# MWPR1516 register map
Vendor: Freescale Semiconductor, Inc.; Series: Kinetis; File version: 1.6
CPU: CM0PLUS r0p0, little endian, no MPU, no FPU, VTOR, 2 interrupt priority bits
Registers are 8-bit, read-write, reset 0x0 unless marked. A register's access mark holds for its fields unless they carry their own. Offsets are from the block's base; [hi:lo] are bit positions; {n}, {i} and the like mark numbered series.

## PORT — Port control and interrupts
Base 0x40049000; register names take the prefix PORT_
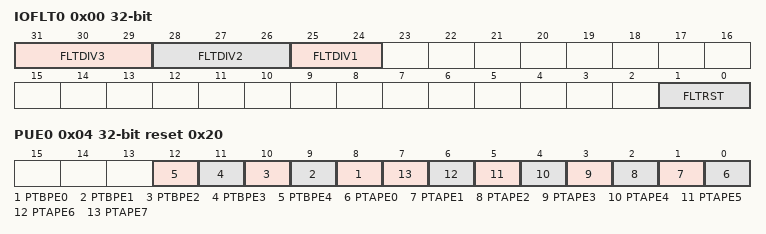
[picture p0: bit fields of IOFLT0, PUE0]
0x00 IOFLT0 32-bit — Port Filter Control Register 0
  [31:29] FLTDIV3 — Filter Division Set 3
    0=LPOCLK; 1=LPOCLK/2; 2=LPOCLK/4; 3=LPOCLK/8; 4=LPOCLK/16; 5=LPOCLK/32; 6=LPOCLK/64; 7=LPOCLK/128
  [28:26] FLTDIV2 — Filter Division Set 2
    0=BUSCLK/32; 1=BUSCLK/64; 2=BUSCLK/128; 3=BUSCLK/256; 4=BUSCLK/512; 5=BUSCLK/1024; 6=BUSCLK/2048; 7=BUSCLK/4096
  [25:24] FLTDIV1 — Filter Division Set 1
    0=BUSCLK/2; 1=BUSCLK/4; 2=BUSCLK/8; 3=BUSCLK/16
  [1:0] FLTRST — Filter Selection for Input from RESET
    0=No filter; 1=Selects FLTDIV1, and will switch to FLTDIV3 in Stop mode automatically; 2=Selects FLTDIV2, and will switch to FLTDIV3 in Stop mode automatically; 3=FLTDIV3
0x04 PUE0 32-bit reset 0x20 — Port Pullup Enable Register 0
  [n+8] PTBPE{n} (n=0..4) — Pull Enable for Port B Bit {n}
    0=Pullup is disabled for port B bit {n}; 1=Pullup is enabled for port B bit {n}
  [n] PTAPE{n} (n=0..7) — Pull Enable for Port A Bit {n}
    0=Pullup is disabled for port A bit {n}; 1=Pullup is enabled for port A bit {n}

## WDOG — Watchdog timer
Base 0x40052000; register names take the prefix WDOG_
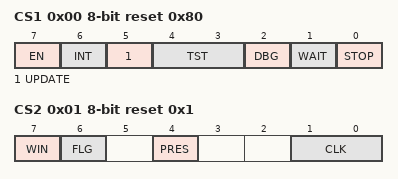
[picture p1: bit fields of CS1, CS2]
0x00 CS1 reset 0x80 — Watchdog Control and Status Register 1
  [7] EN — Watchdog Enable
    0=Watchdog disabled; 1=Watchdog enabled
  [6] INT — Watchdog Interrupt
    0=Watchdog interrupts are disabled. Watchdog resets are not delayed.; 1=Watchdog interrupts are enabled. Watchdog resets are delayed by 128 bus clocks.
  [5] UPDATE — Allow updates
    0=Updates not allowed. After the initial configuration, the watchdog cannot be later modified without forcing a reset.; 1=Updates allowed. Software can modify the watchdog configuration registers within 128 bus clocks after performing the unlock write sequence.
  [4:3] TST — Watchdog Test
    0=Watchdog test mode disabled; 1=Watchdog user mode enabled. (Watchdog test mode disabled.) After testing the watchdog, software should use this setting to indicate that the watchdog is functioning normally in user mode.; 2=Watchdog test mode enabled, only the low byte is used. WDOG_CNTL is compared with WDOG_TOVALL.; 3=Watchdog test mode enabled, only the high byte is used. WDOG_CNTH is compared with WDOG_TOVALH.
  [2] DBG — Debug Enable
    0=Watchdog disabled in chip debug mode; 1=Watchdog enabled in chip debug mode
  [1] WAIT — Wait Enable
    0=Watchdog disabled in chip wait mode; 1=Watchdog enabled in chip wait mode
  [0] STOP — Stop Enable
    0=Watchdog disabled in chip stop mode; 1=Watchdog enabled in chip stop mode
0x01 CS2 reset 0x1 — Watchdog Control and Status Register 2
  [7] WIN — Watchdog Window
    0=Window mode disabled; 1=Window mode enabled
  [6] FLG — Watchdog Interrupt Flag
    0=No interrupt occurred; 1=An interrupt occurred
  [4] PRES — Watchdog Prescalar
    0=256 prescalar disabled; 1=256 prescalar enabled
  [1:0] CLK — Watchdog Clock
    0=Bus clock; 1=20 kHz internal low-power oscillator (LPOCLK); 2=32 kHz internal oscillator (ICSIRCLK); 3=External clock source
0x02 CNT 16-bit (WDOG view) — Watchdog Counter Register.
  [15:0] CNT — Watchdog Counter Value
0x02 CNTH ro (WDOG view) — Watchdog Counter Register: High
  [7:0] CNTHIGH — High byte of the Watchdog Counter
0x03 CNTL ro reset 0xFF — Watchdog Counter Register: Low
  [7:0] CNTLOW — Low byte of the Watchdog Counter
0x04 TOVALH (WDOG view) — Watchdog Timeout Value Register: High
  [7:0] TOVALHIGH — High byte of the timeout value
0x04 TOVAL 16-bit (WDOG view) — Watchdog Timeout Value Register.
  [15:0] TOVAL — Watchdog Timeout Value
0x05 TOVALL reset 0x4 — Watchdog Timeout Value Register: Low
  [7:0] TOVALLOW — Low byte of the timeout value
0x06 WINH (WDOG view) — Watchdog Window Register: High
  [7:0] WINHIGH — High byte of Watchdog Window
0x06 WIN 16-bit (WDOG view) — Watchdog Window Register.
  [15:0] WIN — Watchdog Window Value
0x07 WINL — Watchdog Window Register: Low
  [7:0] WINLOW — Low byte of Watchdog Window
